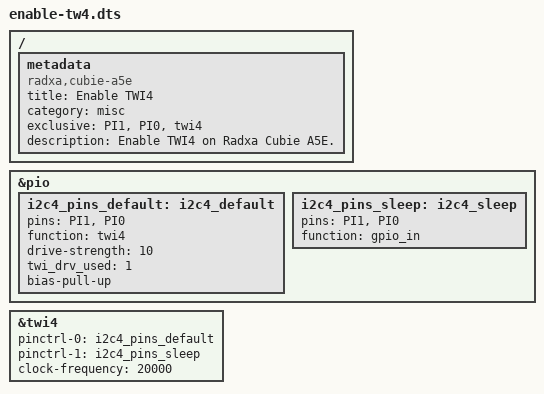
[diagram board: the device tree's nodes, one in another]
/dts-v1/;
/plugin/;
/*
	compatible = "allwinner,sun55i-a523", "allwinner,sun55i-a527";
*/

/ {
    metadata {
        title = "Enable TWI4";
        compatible = "radxa,cubie-a5e";
        category = "misc";
        exclusive = "PI1", "PI0", "twi4";
        description = "Enable TWI4 on Radxa Cubie A5E.";
    };
};

&pio {
    i2c4_pins_default: i2c4_default {
        pins = "PI1", "PI0";
        function = "twi4";
        drive-strength = <10>;
        twi_drv_used = <1>;
        bias-pull-up;
    };
    i2c4_pins_sleep: i2c4_sleep {
        pins = "PI1", "PI0";
        function = "gpio_in";
    };
};

&twi4 {
    pinctrl-names = "default", "sleep";
    pinctrl-0 = <&i2c4_pins_default>;
    pinctrl-1 = <&i2c4_pins_sleep>;
    clock-frequency = <20000>;
    status = "okay";
};
